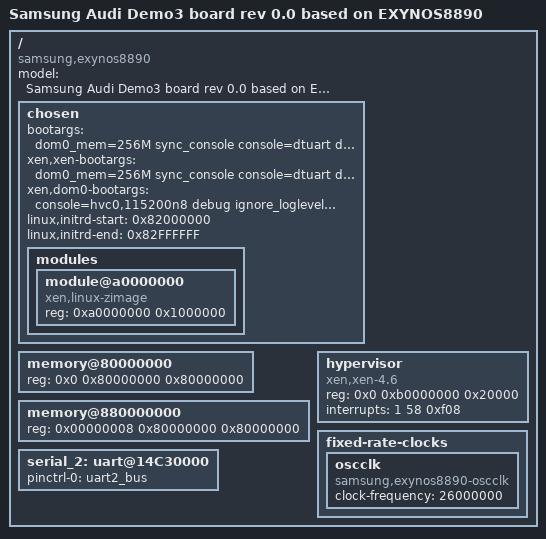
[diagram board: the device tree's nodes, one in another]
/*
 * SAMSUNG Exynos8890 Audi Demo3 board device tree source
 *
 * Copyright (c) 2016 Samsung Electronics Co., Ltd.
 *		http://www.samsung.com
 *
 * This program is free software; you can redistribute it and/or modify
 * it under the terms of the GNU General Public License version 2 as
 * published by the Free Software Foundation.
*/

/dts-v1/;
#include "exynos8890-evt1-dom0.dtsi"
#include "exynos8890-evt1-rmem.dtsi"

/ {
	model = "Samsung Audi Demo3 board rev 0.0 based on EXYNOS8890";
	compatible = "samsung,exynos8890", "samsung,AUDI8890";

	chosen {
		bootargs = "dom0_mem=256M sync_console console=dtuart dtuart=uart2";
		xen,xen-bootargs = "dom0_mem=256M sync_console console=dtuart dtuart=uart2";
		xen,dom0-bootargs = "console=hvc0,115200n8 debug ignore_loglevel earlycon=xen clk_ignore_unused ess_setup=0x86000000 pmic_info=3 androidboot.hardware=samsungexynos8890 androidboot.selinux=permissive";
		linux,initrd-start = <0x82000000>;
		linux,initrd-end = <0x82FFFFFF>;
		modules {
			#address-cells = <1>;
			#size-cells = <1>;
			module@a0000000 {
				 compatible = "xen,linux-zimage", "xen,multiboot-module";
				 reg = <0xa0000000 0x1000000>;
			};
		};
	};

	memory@80000000 {
		device_type = "memory";
		reg = <0x0 0x80000000 0x80000000>;
	};
	memory@880000000 {
		device_type = "memory";
		reg = <0x00000008 0x80000000 0x80000000>;
	};

	hypervisor {
		compatible = "xen,xen-4.6", "xen,xen";
		reg = <0x0 0xb0000000 0x20000>;
		interrupts = <1 58 0xf08>;
	};

	fixed-rate-clocks {
		oscclk {
			compatible = "samsung,exynos8890-oscclk";
			clock-frequency = <26000000>;
		};
	};

	serial_2: uart@14C30000 {
		/* Enable UART channel for debug port */
		pinctrl-names = "default";
		pinctrl-0 = <&uart2_bus>;
		status = "okay";
	};
};
